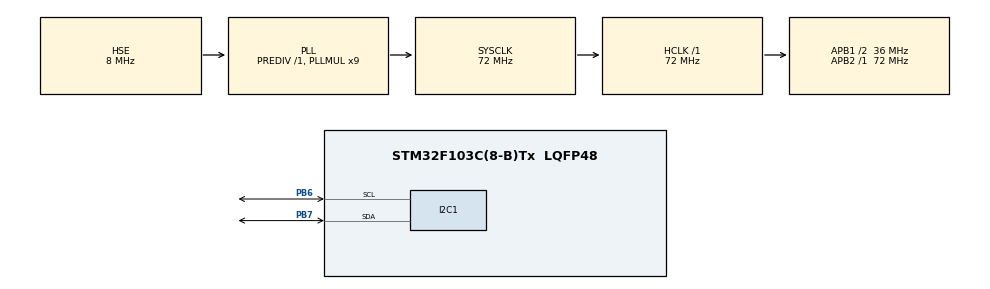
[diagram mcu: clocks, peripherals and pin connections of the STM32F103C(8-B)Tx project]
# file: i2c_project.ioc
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Mcu.Family=STM32F1
Mcu.Name=STM32F103C(8-B)Tx
Mcu.Package=LQFP48
NVIC.I2C1_ER_IRQn=true\:1\:0\:true\:false\:true\:true\:true\:true
NVIC.I2C1_EV_IRQn=true\:1\:0\:true\:false\:true\:true\:true\:true
NVIC.PriorityGroup=NVIC_PRIORITYGROUP_4
PA13.Mode=Serial_Wire
PA13.Signal=SYS_JTMS-SWDIO
PA14.Mode=Serial_Wire
PA14.Signal=SYS_JTCK-SWCLK
PB6.Mode=I2C
PB6.Signal=I2C1_SCL
PB7.Mode=I2C
PB7.Signal=I2C1_SDA
PD0-OSC_IN.Mode=HSE-External-Oscillator
PD0-OSC_IN.Signal=RCC_OSC_IN
PD1-OSC_OUT.Mode=HSE-External-Oscillator
PD1-OSC_OUT.Signal=RCC_OSC_OUT
ProjectManager.HeapSize=0x200
ProjectManager.StackSize=0x400
ProjectManager.TargetToolchain=STM32CubeIDE
RCC.AHBFreq_Value=72000000
RCC.APB1CLKDivider=RCC_HCLK_DIV2
RCC.APB1Freq_Value=36000000
RCC.APB1TimFreq_Value=72000000
RCC.APB2Freq_Value=72000000
RCC.APB2TimFreq_Value=72000000
RCC.HCLKFreq_Value=72000000
RCC.PLLMUL=RCC_PLL_MUL9
RCC.PLLSourceVirtual=RCC_PLLSOURCE_HSE
RCC.SYSCLKFreq_VALUE=72000000
RCC.SYSCLKSource=RCC_SYSCLKSOURCE_PLLCLK
RCC.USBFreq_Value=72000000
board=custom

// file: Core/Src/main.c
/* USER CODE BEGIN Header */
/**
  ******************************************************************************
  * @file           : main.c
  * @brief          : Main program body
  ******************************************************************************
  * @attention
  *
  * Copyright (c) 2023 STMicroelectronics.
  * All rights reserved.
  *
  * This software is licensed under terms that can be found in the LICENSE file
  * in the root directory of this software component.
  * If no LICENSE file comes with this software, it is provided AS-IS.
  *
  ******************************************************************************
  */
/* USER CODE END Header */
#include "main.h"

I2C_HandleTypeDef hi2c1;

/* USER CODE BEGIN PV */

#define DS3231_ADD (0x68<<1)
typedef struct{
	uint8_t sec;
	uint8_t min;
	uint8_t hour;
	uint8_t day;
	uint8_t date;
	uint8_t month;
	uint32_t year;
}DS3231_Struct;
DS3231_Struct ds3231;

// Bin to DEC
uint8_t B_to_D (uint8_t num){
	return ((num/10 * 16) + (num%10));

}

// DEC to Bin
uint8_t D_to_B (uint8_t num){
	return ((num/16 *10) + (num%16));
}

void DS3231_getTime(){
	uint8_t buffer[7];
	HAL_I2C_Master_Transmit(&hi2c1, DS3231_ADD|1, 0x00, 1, 1000);
	HAL_I2C_Master_Receive(&hi2c1, DS3231_ADD, buffer, 7, 1000);
	/* read time*/
	//ds3231.sec   = B_to_D(buffer[0]);
	ds3231.sec   = ((buffer[0] >> 4) & 0x07) * 10 + (buffer[0] & 0x0f);
	ds3231.min   =    ((buffer[1] >> 4) & 0x07) * 10 + (buffer[1] & 0x0f);
	ds3231.hour  =  ((buffer[2] >> 4) & 0x03) * 10 + (buffer[2] & 0x0f);
	ds3231.day   =  buffer[3] & 0x07;
	ds3231.date  = ((buffer[4] >> 4) & 0x03) * 10 + (buffer[4] & 0x0f);
	ds3231.month = ((buffer[5] >> 4) & 0x01) * 10 + (buffer[5] & 0x0f);
	ds3231.year  = ((buffer[6] >> 4) & 0x03) * 10 + (buffer[6] & 0x0f);
}
void DS3231_setTime(uint8_t sec, uint8_t min, uint8_t hour, uint8_t day, uint8_t date, uint8_t month, uint8_t year){
	uint8_t buffer[8];
	buffer[0] = 0x00;
	buffer[1] = (sec / 10) << 4 | ( sec % 10);
	buffer[2] = (min / 10) << 4 | ( min % 10);
	buffer[3] = (hour / 10) << 4 | ( hour % 10);
	buffer[4] = D_to_B(day);
	buffer[5] = (date / 10) << 4 | ( date % 10);
	buffer[6] = (month / 10) << 4 | ( month % 10);
	buffer[7] = (year / 10) << 4 | ( year % 10);
	HAL_I2C_Master_Transmit(&hi2c1, DS3231_ADD|1, buffer, 8, 1000);
}
/* USER CODE END PV */

void SystemClock_Config(void);
static void MX_GPIO_Init(void);
static void MX_I2C1_Init(void);

int main(void)
{

  /* MCU Configuration--------------------------------------------------------*/

  /* Reset of all peripherals, Initializes the Flash interface and the Systick. */
  HAL_Init();

  /* Configure the system clock */
  SystemClock_Config();

  /* Initialize all configured peripherals */
  MX_GPIO_Init();
  MX_I2C1_Init();
  /* USER CODE BEGIN 2 */
  DS3231_setTime(55, 59, 23, 2, 31, 12, 23);

  /* USER CODE END 2 */

  /* Infinite loop */
  while (1)
  {

    /* USER CODE BEGIN 3 */
	  DS3231_getTime();
	  HAL_Delay(1000);
  }
  /* USER CODE END 3 */
}

void SystemClock_Config(void)
{
  RCC_OscInitTypeDef RCC_OscInitStruct = {0};
  RCC_ClkInitTypeDef RCC_ClkInitStruct = {0};

  /** Initializes the RCC Oscillators according to the specified parameters
  * in the RCC_OscInitTypeDef structure.
  */
  RCC_OscInitStruct.OscillatorType = RCC_OSCILLATORTYPE_HSE;
  RCC_OscInitStruct.HSEState = RCC_HSE_ON;
  RCC_OscInitStruct.HSEPredivValue = RCC_HSE_PREDIV_DIV1;
  RCC_OscInitStruct.HSIState = RCC_HSI_ON;
  RCC_OscInitStruct.PLL.PLLState = RCC_PLL_ON;
  RCC_OscInitStruct.PLL.PLLSource = RCC_PLLSOURCE_HSE;
  RCC_OscInitStruct.PLL.PLLMUL = RCC_PLL_MUL9;
  if (HAL_RCC_OscConfig(&RCC_OscInitStruct) != HAL_OK)
  {
    Error_Handler();
  }

  /** Initializes the CPU, AHB and APB buses clocks
  */
  RCC_ClkInitStruct.ClockType = RCC_CLOCKTYPE_HCLK|RCC_CLOCKTYPE_SYSCLK
                              |RCC_CLOCKTYPE_PCLK1|RCC_CLOCKTYPE_PCLK2;
  RCC_ClkInitStruct.SYSCLKSource = RCC_SYSCLKSOURCE_PLLCLK;
  RCC_ClkInitStruct.AHBCLKDivider = RCC_SYSCLK_DIV1;
  RCC_ClkInitStruct.APB1CLKDivider = RCC_HCLK_DIV2;
  RCC_ClkInitStruct.APB2CLKDivider = RCC_HCLK_DIV1;

  if (HAL_RCC_ClockConfig(&RCC_ClkInitStruct, FLASH_LATENCY_2) != HAL_OK)
  {
    Error_Handler();
  }
}

static void MX_I2C1_Init(void)
{

  hi2c1.Instance = I2C1;
  hi2c1.Init.ClockSpeed = 100000;
  hi2c1.Init.DutyCycle = I2C_DUTYCYCLE_2;
  hi2c1.Init.OwnAddress1 = 0;
  hi2c1.Init.AddressingMode = I2C_ADDRESSINGMODE_7BIT;
  hi2c1.Init.DualAddressMode = I2C_DUALADDRESS_DISABLE;
  hi2c1.Init.OwnAddress2 = 0;
  hi2c1.Init.GeneralCallMode = I2C_GENERALCALL_DISABLE;
  hi2c1.Init.NoStretchMode = I2C_NOSTRETCH_DISABLE;
  if (HAL_I2C_Init(&hi2c1) != HAL_OK)
  {
    Error_Handler();
  }

}

static void MX_GPIO_Init(void)
{

  /* GPIO Ports Clock Enable */
  __HAL_RCC_GPIOD_CLK_ENABLE();
  __HAL_RCC_GPIOA_CLK_ENABLE();
  __HAL_RCC_GPIOB_CLK_ENABLE();

}

void Error_Handler(void)
{
  __disable_irq();
  while (1)
  {
  }
}
